# nrf54lm20a_enga_flpr register map
Vendor: Nordic Semiconductor; Series: nrf54l; File version: 1
Registers are 32-bit, read-write, reset 0x0 unless marked. A register's access mark holds for its fields unless they carry their own. Offsets are from the block's base; [hi:lo] are bit positions; lines under a group give offsets from that group; {n}, {i} and the like mark numbered series; 'fields as' and 'values as' point back to an identical list.

## GLOBAL_SREGS00_NS — Spare registers 0
Base 0x4007E000
Same registers: GLOBAL_SREGS10_NS 0x4008C000, GLOBAL_SREGS20_NS 0x400E6000, GLOBAL_SREGS30_NS 0x4010F000, GLOBAL_SREGS00_S 0x5007E000, GLOBAL_SREGS10_S 0x5008C000, GLOBAL_SREGS20_S 0x500E6000, GLOBAL_SREGS30_S 0x5010F000
{0x500+4i} REG[{i}] (i=0..1) — Description collection: Spare register n
  [31:0] VALUE
0x580 TESTREG — Test special register
  [3:0] TESTFIELD
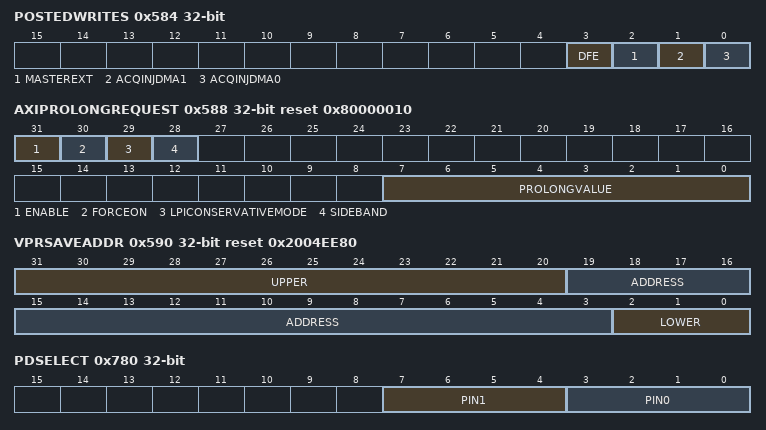
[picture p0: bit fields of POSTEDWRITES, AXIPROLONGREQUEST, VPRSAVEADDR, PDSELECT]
0x584 POSTEDWRITES — Enable or disable posted writes functionality for specific AXI/AHB bus masters
  [all] fields
    0=Disabled (Disable posted writes); 1=Enabled (Enable posted writes)
  [3] DFE — Disable or enable posted writes for Radio AHB for Direction Finding
  [2] MASTEREXT — Disable or enable posted writes for Radio AHB for Radio packets
  [1] ACQINJDMA1 — Disable or enable posted writes for Radio ACQINJDMA1
  [0] ACQINJDMA0 — Disable or enable posted writes for Radio ACQINJDMA0
0x588 AXIPROLONGREQUEST reset 0x80000010 — Configuration of the AxiRequestProlonger module.
  [31] ENABLE — Disable or enable the prolong functionality
    0=Disabled (Disable prolong functionality); 1=Enabled (Enable prolong functionality)
  [30] FORCEON — Disable or enable constant prolong request
    0=Disabled (Disable FORCEON); 1=Enabled (Enable FORCEON)
  [29] LPICONSERVATIVEMODE — Disable or enable LPI conservative mode
    values as the fields of POSTEDWRITES
  [28] SIDEBAND — Disable or enable additional sideband request
    0=Disabled (Disable sideband); 1=Enabled (Enable sideband)
  [7:0] PROLONGVALUE — Number of additional clocks the request is prolonged
0x58C RADIOSIDEBANDREQUEST — Sideband request from Radio to LRC.
  [0] SIDEBAND — Disable or enable sideband request for Radio
    0=Disabled (Disable sideband request); 1=Enabled (Enable sideband request)
0x590 VPRSAVEADDR reset 0x2004EE80 — VPR context save address.
  [31:20] UPPER ro — VPR context store address, upper range (static)
  [19:3] ADDRESS — VPR context store address
  [2:0] LOWER ro — VPR context store address, lower range (static)
{0x600+4i} MAINREG[{i}] (i=0..0) — Description collection: Spare register n in PD_MAIN
  [7:0] VALUE
{0x700+4i} AOREG[{i}] (i=0..0) — Description collection: Spare register n in PD_AO
  [3:0] VALUE
0x704 AODFT — AO control of DFT features
  [0] DTBENABLE — Output DTB on GPIO pins through Always-On pin muxing
0x780 PDSELECT — Power domain status selection
  [7:4] PIN1 — Mapping for pin P0.04
    0=Disable (pin is used as regular pin); 1=PdMain (Shows if PD_MAIN is on); 2=PdLp (Shows if PD_LP is on); 3=PdPeri (Shows if PD_M (also called PD_PERI) is on); 4=PdMcu (Shows if PD_MCU is on); 5=PdRadio (Shows if PD_RADIO is on); 6=PdCracen (Shows if PD_AUX (also called PD_CRACEN) is on); 7=PwrAboveElv (Not in Elv mode (pwrAboveElv_a)); 8=RequestPwrAboveElv (System request for ELV mode (requestPwrAboveElv_a)); 9=VregMainPwrupLdo (VREGMAIN (PwrDcdcLdo) power-up LDO signal); 10=VregMainPwrupPfm (VREGMAIN (PwrDcdcLdo) power-up PFM signal); 11=VregMainPwrupPwm (VREGMAIN (PwrDcdcLdo) power-up PWM signal)
  [3:0] PIN0 — Mapping for pin P0.03
    values as PIN1

## GLOBAL_SUPPORT00_S — PCGCSlave 0
Base 0x5007F000
Same registers: GLOBAL_SUPPORT10_S 0x5009E000, GLOBAL_SUPPORT20_S 0x500FF000, GLOBAL_PCGCS30_S 0x5011E000, GLOBAL_SUPPORT30_S 0x5011F000
{0xC00+4i} PENALTY[{i}] (i=0..1) — Description collection: Penalty level for power/clock pair n
  [7:0] PENALTY — Penalty level
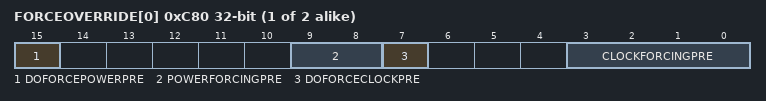
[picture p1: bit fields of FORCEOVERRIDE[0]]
{0xC80+4i} FORCEOVERRIDE[{i}] (i=0..1) — Description collection: Force override of power/clock pair n
  [15] DOFORCEPOWERPRE, [9:8] POWERFORCINGPRE, [7] DOFORCECLOCKPRE, [3:0] CLOCKFORCINGPRE

## GLOBAL_MEMCONF_NS — Memory configuration 0
Base 0x400CF000
Same registers: GLOBAL_MEMCONF_S 0x500CF000
{0x500+0x10*i} POWER[{i}] (i=0..1) group — Unspecified
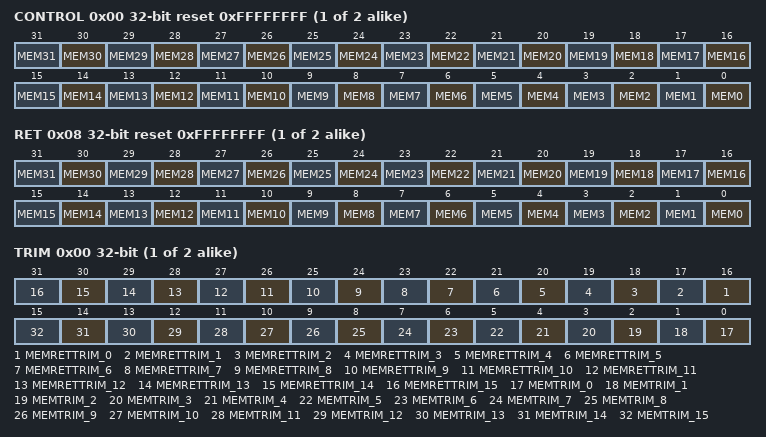
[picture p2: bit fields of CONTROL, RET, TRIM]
  0x00 CONTROL reset 0xFFFFFFFF — Description cluster: Control memory block power.
    [all] fields
      0=Off (Power down); 1=On (Power up)
    [n] MEM{n} (n=0..31) — Keep the memory block MEM[{n}] on or off when in System ON mode.
  0x08 RET reset 0xFFFFFFFF — Description cluster: RAM retention for RAM [n].
    [all] fields
      0=Off (Retention off); 1=On (Retention on)
    [n] MEM{n} (n=0..31) — Keep the RAM block MEM[{n}] retained when in System OFF mode.
{0x900+4i} BLOCKTYPE[{i}] (i=0..1) group — Unspecified
  0x00 TRIM — Description cluster: Trim configuration for the memory block types.
    [n+16] MEMRETTRIM_{n} (n=0..15) — Trimming for retention mode for decreased leakage. Must be kept active in RAM retention mode.
    [n] MEMTRIM_{n} (n=0..15) — Read/write margin trim.
